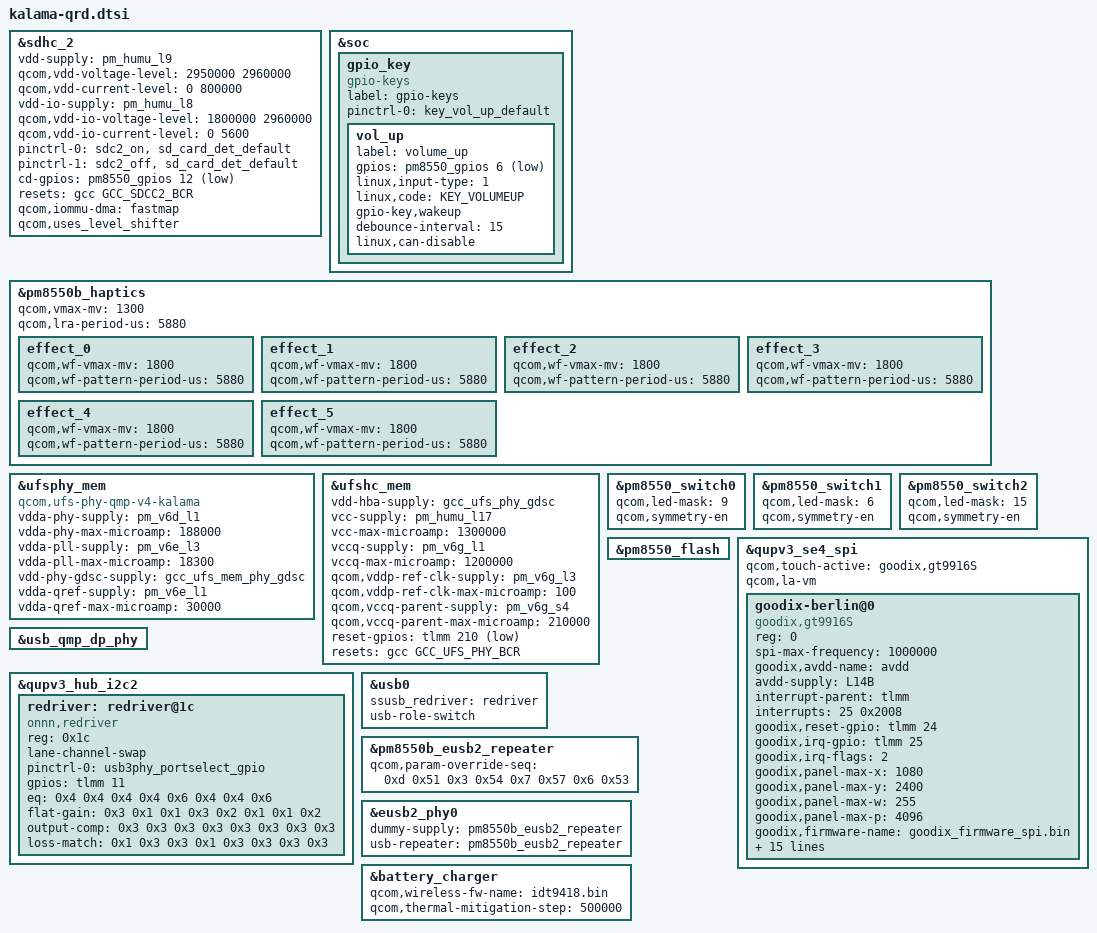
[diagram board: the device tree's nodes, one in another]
#include <dt-bindings/gpio/gpio.h>
#include <dt-bindings/input/input.h>
#include <dt-bindings/clock/qcom,gcc-kalama.h>

#include "kalama-pmic-overlay.dtsi"
#include "kalama-thermal-overlay.dtsi"

&sdhc_2 {
	status = "ok";
	vdd-supply = <&pm_humu_l9>;
	qcom,vdd-voltage-level = <2950000 2960000>;
	qcom,vdd-current-level = <0 800000>;

	vdd-io-supply = <&pm_humu_l8>;
	qcom,vdd-io-voltage-level = <1800000 2960000>;
	qcom,vdd-io-current-level = <0 5600>;

	pinctrl-names = "default", "sleep";
	pinctrl-0 = <&sdc2_on>, <&sd_card_det_default>;
	pinctrl-1 = <&sdc2_off>, <&sd_card_det_default>;

	cd-gpios = <&pm8550_gpios 12 GPIO_ACTIVE_LOW>;

	resets = <&gcc GCC_SDCC2_BCR>;
	reset-names = "core_reset";

	qcom,iommu-dma = "fastmap";
	qcom,uses_level_shifter;
};

&soc {
	gpio_key {
		compatible = "gpio-keys";
		label = "gpio-keys";

		pinctrl-names = "default";
		pinctrl-0 = <&key_vol_up_default>;

		vol_up {
			label = "volume_up";
			gpios = <&pm8550_gpios 6 GPIO_ACTIVE_LOW>;
			linux,input-type = <1>;
			linux,code = <KEY_VOLUMEUP>;
			gpio-key,wakeup;
			debounce-interval = <15>;
			linux,can-disable;
		};
	};
};

&pm8550b_haptics {
	qcom,vmax-mv = <1300>;
	qcom,lra-period-us = <5880>;
	status = "ok";

	effect_0 {
		/* CLICK */
		qcom,wf-vmax-mv = <1800>;
		qcom,wf-pattern-period-us = <5880>;
	};

	effect_1 {
		/* DOUBLE_CLICK */
		qcom,wf-vmax-mv = <1800>;
		qcom,wf-pattern-period-us = <5880>;
	};

	effect_2 {
		/* TICK */
		qcom,wf-vmax-mv = <1800>;
		qcom,wf-pattern-period-us = <5880>;
	};

	effect_3 {
		/* THUD */
		qcom,wf-vmax-mv = <1800>;
		qcom,wf-pattern-period-us = <5880>;
	};

	effect_4 {
		/* POP */
		qcom,wf-vmax-mv = <1800>;
		qcom,wf-pattern-period-us = <5880>;
	};

	effect_5 {
		/* HEAVY CLICK */
		qcom,wf-vmax-mv = <1800>;
		qcom,wf-pattern-period-us = <5880>;
	};
};

&ufsphy_mem {
	compatible = "qcom,ufs-phy-qmp-v4-kalama";

	/* VDDA_UFS_CORE */
	vdda-phy-supply = <&pm_v6d_l1>;
	vdda-phy-max-microamp = <188000>;

	/* VDDA_UFS_0_1P2 */
	vdda-pll-supply = <&pm_v6e_l3>;
	vdda-pll-max-microamp = <18300>;

	/* Phy GDSC for VDD_MX, always on */
	vdd-phy-gdsc-supply = <&gcc_ufs_mem_phy_gdsc>;

	/* Qref power supply, Refer Qref diagram */
	vdda-qref-supply = <&pm_v6e_l1>;
	vdda-qref-max-microamp = <30000>;

	status = "ok";
};

&ufshc_mem {
	vdd-hba-supply = <&gcc_ufs_phy_gdsc>;

	vcc-supply = <&pm_humu_l17>;
	vcc-max-microamp = <1300000>;

	vccq-supply = <&pm_v6g_l1>;
	vccq-max-microamp = <1200000>;

	/* VDD_PX10 is voted for the ufs_reset_n */
	qcom,vddp-ref-clk-supply = <&pm_v6g_l3>;
	qcom,vddp-ref-clk-max-microamp = <100>;

	qcom,vccq-parent-supply = <&pm_v6g_s4>;
	qcom,vccq-parent-max-microamp = <210000>;

	reset-gpios = <&tlmm 210 GPIO_ACTIVE_LOW>;
	resets = <&gcc GCC_UFS_PHY_BCR>;
	reset-names = "rst";

	status = "ok";
};

&pm8550_switch0 {
	qcom,led-mask = <9>; /* Channels 1 & 4 */
	qcom,symmetry-en;
};

&pm8550_switch1 {
	qcom,led-mask = <6>; /* Channels 2 & 3 */
	qcom,symmetry-en;
};

&pm8550_switch2 {
	qcom,led-mask = <15>; /* All Channels */
	qcom,symmetry-en;
};

&pm8550_flash {
	status = "ok";
};

&qupv3_se4_spi {
	#address-cells = <1>;
	#size-cells = <0>;
	status = "ok";
	qcom,touch-active = "goodix,gt9916S";
	qcom,la-vm;

	goodix-berlin@0 {
		compatible = "goodix,gt9916S";
		reg = <0>;
		spi-max-frequency = <1000000>;

		goodix,avdd-name = "avdd";
		avdd-supply = <&L14B>;

		interrupt-parent = <&tlmm>;
		interrupts = <25 0x2008>;
		goodix,reset-gpio = <&tlmm 24 0x00>;
		goodix,irq-gpio = <&tlmm 25 0x2008>;
		goodix,irq-flags = <2>;
		goodix,panel-max-x = <1080>;
		goodix,panel-max-y = <2400>;
		goodix,panel-max-w = <255>;
		goodix,panel-max-p = <4096>;
		goodix,firmware-name = "goodix_firmware_spi.bin";
		goodix,config-name = "goodix_cfg_group_spi.bin";

		pinctrl-names = "pmx_ts_active", "pmx_ts_suspend", "pmx_ts_release";
		pinctrl-0 = <&ts_active>;
		pinctrl-1 = <&ts_int_suspend &ts_reset_suspend>;
		pinctrl-2 = <&ts_release>;

		goodix,touch-type = "primary";
		goodix,qts_en;
		qts,trusted-touch-mode = "vm_mode";
		qts,touch-environment = "pvm";
		qts,trusted-touch-type = "primary";
		qts,trusted-touch-spi-irq = <569>;
		qts,trusted-touch-io-bases = <0xa90000>;
		qts,trusted-touch-io-sizes = <0x1000>;
		qts,trusted-touch-vm-gpio-list = <&tlmm 44 0 &tlmm 45 0 &tlmm 46 0
						&tlmm 47 0 &tlmm 24 0 &tlmm 25 0x2008>;
	};
};

&usb_qmp_dp_phy {
	pinctrl-names = "unused";
};

&qupv3_hub_i2c2 {
	status = "ok";

	#address-cells = <1>;
	#size-cells = <0>;
	redriver: redriver@1c {
		compatible = "onnn,redriver";
		reg = <0x1c>;

		lane-channel-swap;

		pinctrl-names = "default";
		pinctrl-0 = <&usb3phy_portselect_gpio>;
		gpios = <&tlmm 11 0>;

		eq = /bits/ 8 <
				/* Parameters for USB */
				0x4 0x4 0x4 0x4
				/* Parameters for DP */
				0x6 0x4 0x4 0x6>;
		flat-gain = /bits/ 8 <
				/* Parameters for USB */
				0x3 0x1 0x1 0x3
				/* Parameters for DP */
				0x2 0x1 0x1 0x2>;
		output-comp = /bits/ 8 <
				/* Parameters for USB */
				0x3 0x3 0x3 0x3
				/* Parameters for DP */
				0x3 0x3 0x3 0x3>;
		loss-match = /bits/ 8 <
				/* Parameters for USB */
				0x1 0x3 0x3 0x1
				/* Parameters for DP */
				0x3 0x3 0x3 0x3>;
	};
};

&usb0 {
	ssusb_redriver = <&redriver>;
};

&pm8550b_eusb2_repeater {
	qcom,param-override-seq =
		/* <value reg_offset> */
		/* Adjust HS trasmit amplitude */
		<0xd 0x51
		/* Squelch detection threshold */
		 0x3 0x54
		/* Tx pre-emphasis tuning */
		 0x7 0x57
		/* HS disconnect threshold */
		 0x6 0x53>;
};

&eusb2_phy0 {
	dummy-supply = <&pm8550b_eusb2_repeater>;
	usb-repeater = <&pm8550b_eusb2_repeater>;
};

&usb0 {
	usb-role-switch;
};

&battery_charger {
	qcom,wireless-fw-name = "idt9418.bin";
	qcom,thermal-mitigation-step = <500000>;
};
